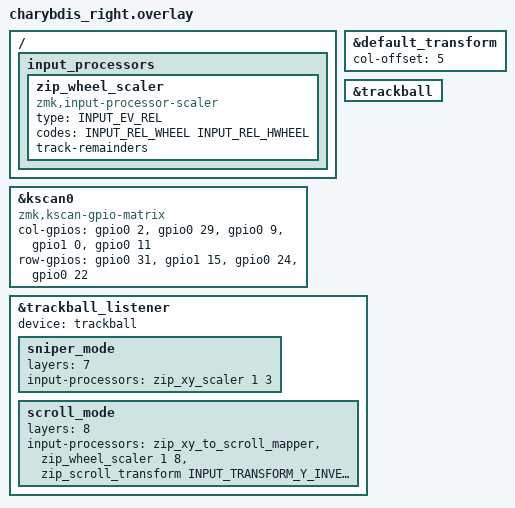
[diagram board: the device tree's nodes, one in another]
#include "charybdis.dtsi"
#include "charybdis_pmw3610.dtsi"
#include "charybdis_pointer.dtsi"
#include <dt-bindings/input/input-event-codes.h>
#include <dt-bindings/zmk/input_transform.h>
#include <input/processors.dtsi>

&default_transform {
    col-offset = <5>;
};

&kscan0 {
    compatible = "zmk,kscan-gpio-matrix";
    
    col-gpios
        = <&gpio0 2 (GPIO_ACTIVE_HIGH | GPIO_PULL_DOWN)>
        , <&gpio0 29 (GPIO_ACTIVE_HIGH | GPIO_PULL_DOWN)>
        , <&gpio0 9 (GPIO_ACTIVE_HIGH | GPIO_PULL_DOWN)>
        , <&gpio1 0 (GPIO_ACTIVE_HIGH | GPIO_PULL_DOWN)>
        , <&gpio0 11 (GPIO_ACTIVE_HIGH | GPIO_PULL_DOWN)>;
    
    row-gpios
        = <&gpio0 31 GPIO_ACTIVE_HIGH>
        , <&gpio1 15 GPIO_ACTIVE_HIGH>
        , <&gpio0 24 GPIO_ACTIVE_HIGH>
        , <&gpio0 22 GPIO_ACTIVE_HIGH>;
};

/* enable trackball */
&trackball {
    status = "okay";
};

/ {
    input_processors {
        zip_wheel_scaler: zip_wheel_scaler {
            compatible = "zmk,input-processor-scaler";
            #input-processor-cells = <2>;
            type = <INPUT_EV_REL>;
            codes = <INPUT_REL_WHEEL INPUT_REL_HWHEEL>;
            track-remainders;
        };
    };
};

/* enable the listener on central */
&trackball_listener {
    status = "okay";
    device = <&trackball>;
    
    // Automouse disabled - can be enabled later by uncommenting the line below
    // input-processors = <&zip_temp_layer 6 500>;
    
    // Sniper mode on SCROLL layer (7) - slow down by 3x (equivalent to ~400 CPI from 1200)
    sniper_mode {
        layers = <7>;
        input-processors = <&zip_xy_scaler 1 3>;
    };
    
    // Scroll mode on layer 8 - inverted smooth scroll (1/8 speed)
    scroll_mode {
        layers = <8>;
        input-processors = <&zip_xy_to_scroll_mapper>, <&zip_wheel_scaler 1 8>, <&zip_scroll_transform INPUT_TRANSFORM_Y_INVERT>;
    };
};
